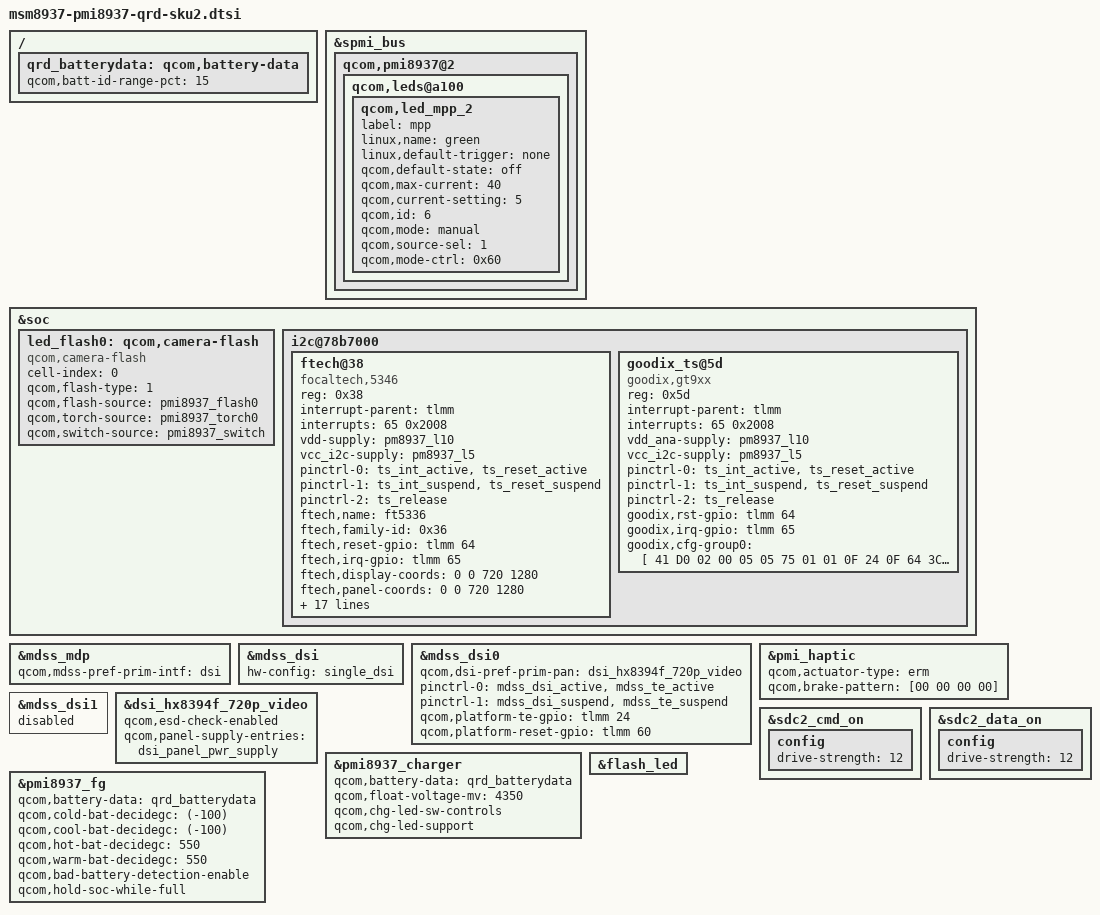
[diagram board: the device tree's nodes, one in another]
/*
 * Copyright (c) 2015-2016, The Linux Foundation. All rights reserved.
 *
 * This program is free software; you can redistribute it and/or modify
 * it under the terms of the GNU General Public License version 2 and
 * only version 2 as published by the Free Software Foundation.
 *
 * This program is distributed in the hope that it will be useful,
 * but WITHOUT ANY WARRANTY; without even the implied warranty of
 * MERCHANTABILITY or FITNESS FOR A PARTICULAR PURPOSE.  See the
 * GNU General Public License for more details.
 */

#include "msm-pmi8937.dtsi"
#include "msm8937-qrd.dtsi"
#include "msm8937-mdss-panels.dtsi"

&spmi_bus {
	qcom,pmi8937@2 {
		qcom,leds@a100 {
			status = "okay";
			qcom,led_mpp_2 {
				label = "mpp";
				linux,name = "green";
				linux,default-trigger = "none";
				qcom,default-state = "off";
				qcom,max-current = <40>;
				qcom,current-setting = <5>;
				qcom,id = <6>;
				qcom,mode = "manual";
				qcom,source-sel = <1>;
				qcom,mode-ctrl = <0x60>;
			};
		};
	};
};

&soc {
	led_flash0: qcom,camera-flash {
		cell-index = <0>;
		compatible = "qcom,camera-flash";
		qcom,flash-type = <1>;
		qcom,flash-source = <&pmi8937_flash0>;
		qcom,torch-source = <&pmi8937_torch0>;
		qcom,switch-source = <&pmi8937_switch>;
	};

	i2c@78b7000 {
		status = "ok";
		   ftech@38 {
				   compatible = "focaltech,5346";
				   reg = <0x38>;
				   interrupt-parent = <&tlmm>;
				   interrupts = <65 0x2008>;
				   vdd-supply = <&pm8937_l10>;
				   vcc_i2c-supply = <&pm8937_l5>;
				   /* pins used by touchscreen */
				   pinctrl-names = "pmx_ts_active","pmx_ts_suspend",
						   "pmx_ts_release";
				   pinctrl-0 = <&ts_int_active &ts_reset_active>;
				   pinctrl-1 = <&ts_int_suspend &ts_reset_suspend>;
				   pinctrl-2 = <&ts_release>;
				   ftech,name = "ft5336";
				   ftech,family-id = <0x36>;
				   ftech,reset-gpio = <&tlmm 64 0x00>;
				   ftech,irq-gpio = <&tlmm 65 0x2008>;
				   ftech,display-coords = <0 0 720 1280>;
				   ftech,panel-coords = <0 0 720 1280>;
				   /*ftech,button-map= <139 102 158>;*/
				   ftech,virtual-key1 = <139 180 2000>;/*menu*/
				   ftech,virtual-key2 = <172 540 2000>;/*home*/
				   ftech,virtual-key3 = <158 900 2000>;/*back*/
				   ftech,no-force-update;
				   ftech,i2c-pull-up;
				   ftech,group-id = <1>;
				   ftech,hard-reset-delay-ms = <20>;
				   ftech,soft-reset-delay-ms = <200>;
				   ftech,num-max-touches = <10>;
				   ftech,fw-delay-aa-ms = <30>;
				   ftech,fw-delay-55-ms = <30>;
				   ftech,fw-upgrade-id1 = <0x79>;
				   ftech,fw-upgrade-id2 = <0x18>;
				   ftech,fw-delay-readid-ms = <10>;
				   ftech,fw-delay-era-flsh-ms = <2000>;
				   ftech,fw-auto-cal;
				   ftech,ignore-id-check;
		};
		goodix_ts@5d {
			compatible = "goodix,gt9xx";
			reg = <0x5d>;
			interrupt-parent = <&tlmm>;
			interrupts = <65 0x2008>;
			vdd_ana-supply = <&pm8937_l10>;
                        vcc_i2c-supply = <&pm8937_l5>;
		        pinctrl-names = "pmx_ts_active","pmx_ts_suspend",
                        "pmx_ts_release";
                       pinctrl-0 = <&ts_int_active &ts_reset_active>;
                        pinctrl-1 = <&ts_int_suspend &ts_reset_suspend>;
                        pinctrl-2 = <&ts_release>;
			goodix,rst-gpio = <&tlmm 64 0x00>;
			goodix,irq-gpio = <&tlmm 65 0x2008>;
			goodix,cfg-group0 = [
				41 D0 02 00 05 05 75 01 01 0F 24
				0F 64 3C 03 05 00 00 00 02 00 00
				00 16 19 1C 14 8C 0E 0E 24 00 31
				0D 00 00 00 83 33 1D 00 41 00 00
				00 00 00 08 0A 00 2B 1C 3C 94 D5
				03 08 00 00 04 93 1E 00 82 23 00
				74 29 00 69 2F 00 5F 37 00 5F 20
				40 60 00 F0 40 30 55 50 27 00 00
				00 00 00 00 00 00 00 00 00 00 00
				00 00 00 00 00 00 00 14 19 00 00
				50 50 02 04 06 08 0A 0C 0E 10 12
				14 16 18 1A 1C 00 00 00 00 00 00
				00 00 00 00 00 00 00 00 00 00 1D
				1E 1F 20 21 22 24 26 28 29 2A 1C
				18 16 14 13 12 10 0F 0C 0A 08 06
				04 02 00 00 00 00 00 00 00 00 00
				00 00 00 00 00 00 00 00 9C 01];
	       };
     };
};

&mdss_mdp {
	qcom,mdss-pref-prim-intf = "dsi";
};

&mdss_dsi {
	hw-config = "single_dsi";
};

&mdss_dsi0 {
	qcom,dsi-pref-prim-pan = <&dsi_hx8394f_720p_video>;
	pinctrl-names = "mdss_default", "mdss_sleep";
	pinctrl-0 = <&mdss_dsi_active &mdss_te_active>;
	pinctrl-1 = <&mdss_dsi_suspend &mdss_te_suspend>;

	qcom,platform-te-gpio = <&tlmm 24 0>;
	qcom,platform-reset-gpio = <&tlmm 60 0>;
};

&pmi_haptic {
	status = "okay";
	qcom,actuator-type = "erm";
	qcom,brake-pattern = [00 00 00 00];
	/delete-property/ qcom,en-brake;
	/delete-property/ qcom,lra-auto-res-mode;
	/delete-property/ qcom,lra-high-z;
	/delete-property/ qcom,lra-res-cal-period;
	/delete-property/ qcom,correct-lra-drive-freq;
	/delete-property/ qcom,misc-trim-error-rc19p2-clk-reg-present;
};

&mdss_dsi1 {
	status = "disabled";
};

&dsi_hx8394f_720p_video {
	qcom,esd-check-enabled;
	qcom,panel-supply-entries = <&dsi_panel_pwr_supply>;
};

&sdc2_cmd_on {
	config {
		drive-strength = <12>;
	};
};

&sdc2_data_on {
	config {
		drive-strength = <12>;
	};
};

/ {
	qrd_batterydata: qcom,battery-data {
		qcom,batt-id-range-pct = <15>;
		#include "batterydata-qrd-sku2-4v35-2590mah.dtsi"
	};
};

&pmi8937_charger {
	qcom,battery-data = <&qrd_batterydata>;
	qcom,float-voltage-mv = <4350>;
	qcom,chg-led-sw-controls;
	qcom,chg-led-support;
	status = "okay";
};

&pmi8937_fg {
	qcom,battery-data = <&qrd_batterydata>;
	qcom,cold-bat-decidegc = <(-100)>;
	qcom,cool-bat-decidegc = <(-100)>;
	qcom,hot-bat-decidegc = <550>;
	qcom,warm-bat-decidegc = <550>;
	qcom,bad-battery-detection-enable;
	qcom,hold-soc-while-full;
};

&flash_led {
	/delete-node/ qcom,flash_1;
	/delete-node/ qcom,torch_1;
};
